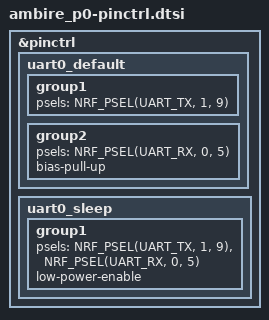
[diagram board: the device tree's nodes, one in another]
/*
 * Ambire Ice proto 0 radio: UART to the STM32 through the TXU0202 translator.
 *
 * Module pad -> nRF52840 pin -> net (as-ordered proto 0 PCB, module U11):
 *   pad 17  P1.09  RADIO_TX  module TX -> TXU0202 B2 -> A2Y -> RADIO_RXD_MCU (STM32 RX)
 *   pad 15  P0.05  RADIO_RX  module RX <- TXU0202 B1Y <- A1 <- RADIO_TXD_MCU (STM32 TX)
 * Two wires only: no RTS/CTS, no handshake GPIOs.
 */

&pinctrl {
	uart0_default: uart0_default {
		group1 {
			psels = <NRF_PSEL(UART_TX, 1, 9)>;
		};
		group2 {
			psels = <NRF_PSEL(UART_RX, 0, 5)>;
			bias-pull-up;
		};
	};

	uart0_sleep: uart0_sleep {
		group1 {
			psels = <NRF_PSEL(UART_TX, 1, 9)>,
				<NRF_PSEL(UART_RX, 0, 5)>;
			low-power-enable;
		};
	};
};
